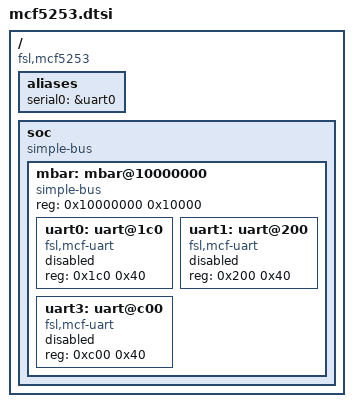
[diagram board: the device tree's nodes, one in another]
// SPDX-License-Identifier: GPL-2.0+
/*
 * Copyright (C) 2018 Angelo Dureghello <angelo@sysam.it>
 */

/ {
	compatible = "fsl,mcf5253";

	aliases {
		serial0 = &uart0;
	};

	soc {
		compatible = "simple-bus";
		#address-cells = <1>;
		#size-cells = <1>;

		mbar: mbar@10000000 {
			compatible = "simple-bus";
			#address-cells = <1>;
			#size-cells = <1>;
			ranges = <0x00000000 0x10000000 0x10000>;
			reg = <0x10000000 0x10000>;

			uart0: uart@1c0 {
				compatible = "fsl,mcf-uart";
				reg = <0x1c0 0x40>;
				status = "disabled";
			};

			uart1: uart@200 {
				compatible = "fsl,mcf-uart";
				reg = <0x200 0x40>;
				status = "disabled";
			};

			uart3: uart@c00 {
				compatible = "fsl,mcf-uart";
				reg = <0xc00 0x40>;
				status = "disabled";
			};
		};
	};
};
